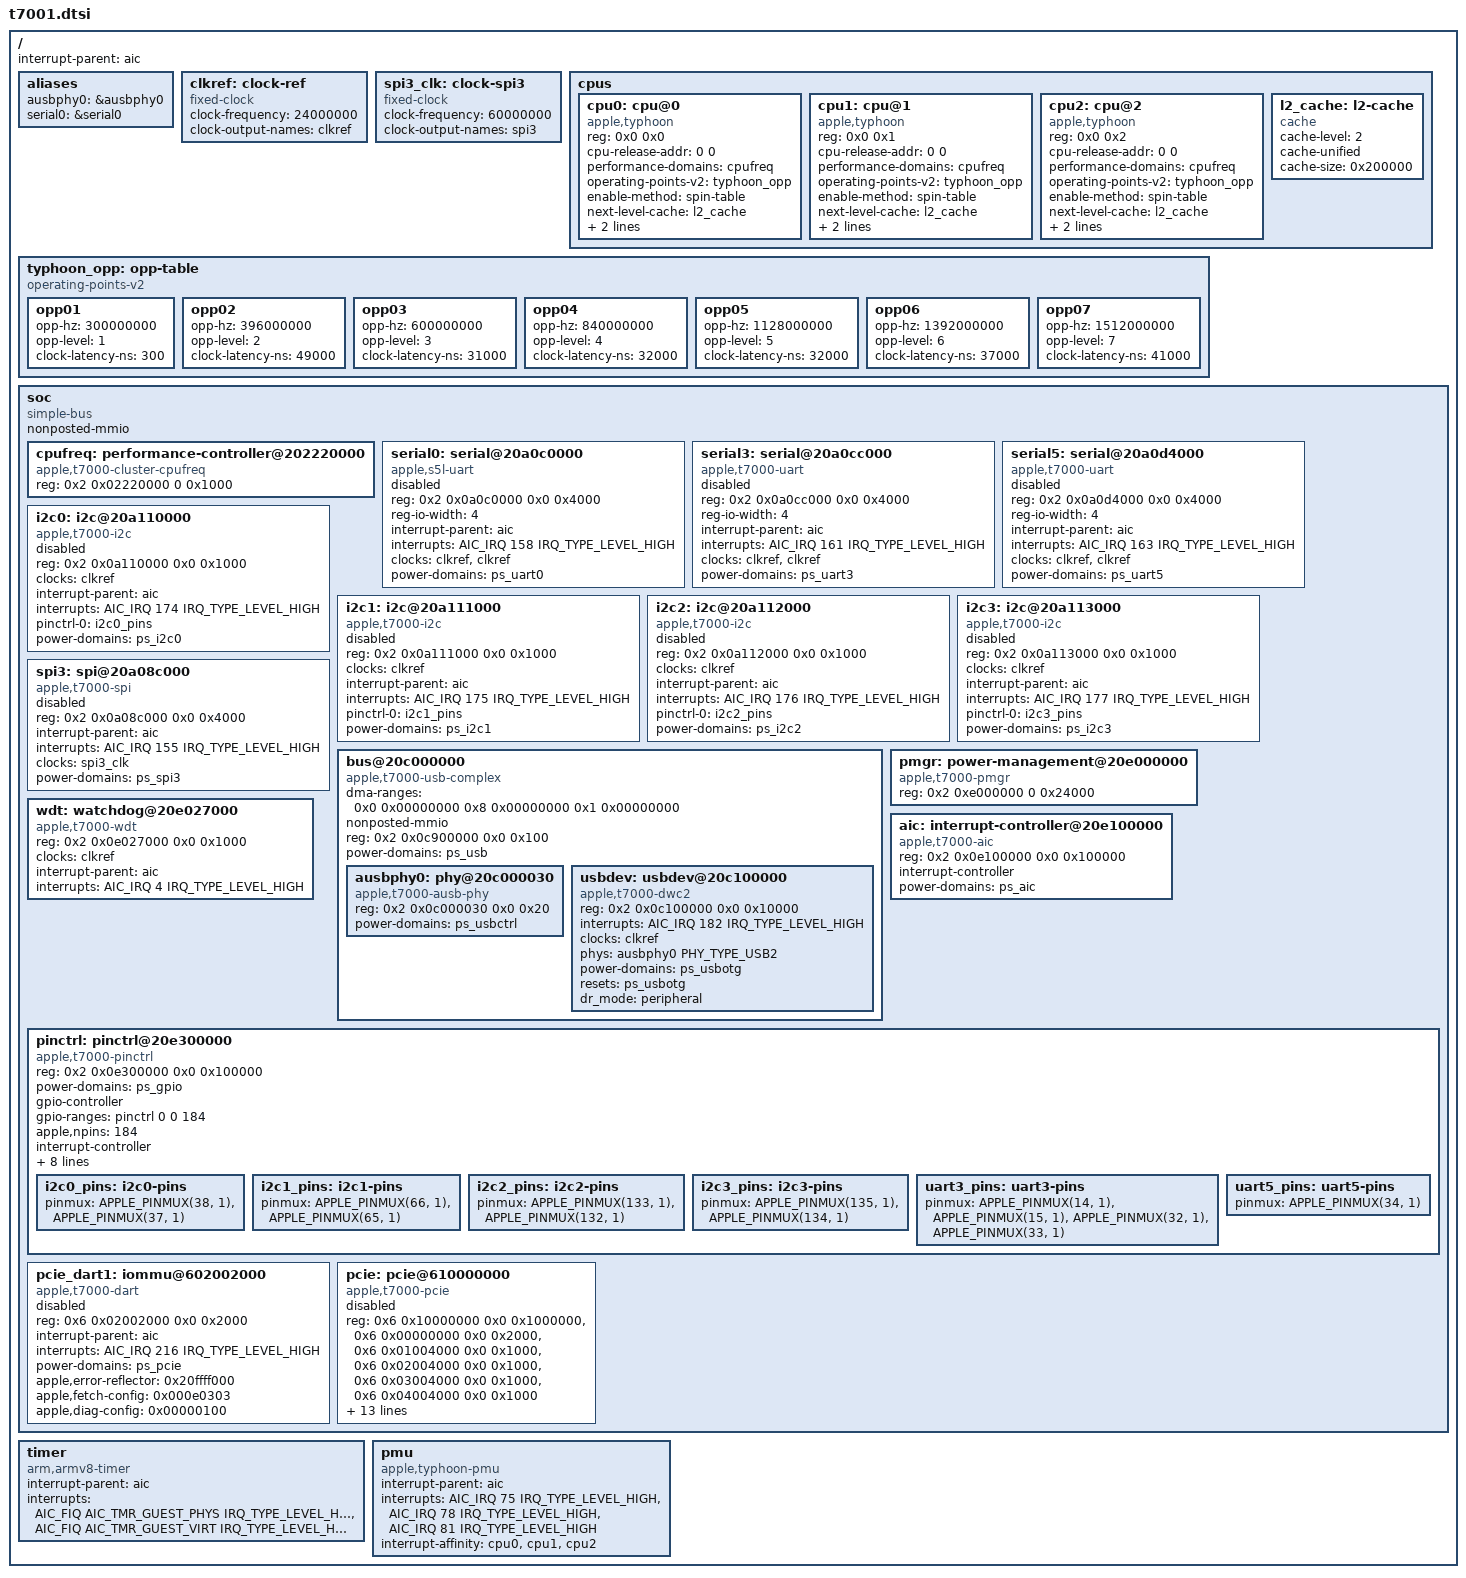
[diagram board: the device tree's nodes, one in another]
// SPDX-License-Identifier: GPL-2.0+ OR MIT
/*
 * Apple T7001 "A8X" SoC
 *
 * Copyright (c) 2022, Konrad Dybcio <konradybcio@kernel.org>
 * Based on Asahi Linux's M1 (t8103.dtsi) and Corellium's A10 efforts.
 */

#include <dt-bindings/gpio/gpio.h>
#include <dt-bindings/interrupt-controller/apple-aic.h>
#include <dt-bindings/interrupt-controller/irq.h>
#include <dt-bindings/phy/phy.h>
#include <dt-bindings/pinctrl/apple.h>

/ {
	interrupt-parent = <&aic>;
	#address-cells = <2>;
	#size-cells = <2>;

	aliases {
		ausbphy0 = &ausbphy0; /* Used by loader */
		serial0 = &serial0;
	};

	clkref: clock-ref {
		compatible = "fixed-clock";
		#clock-cells = <0>;
		clock-frequency = <24000000>;
		clock-output-names = "clkref";
	};

	spi3_clk: clock-spi3 {
		compatible = "fixed-clock";
		#clock-cells = <0>;
		/* ADT clock ID 0x12e: clock-frequencies[46]. */
		clock-frequency = <60000000>;
		clock-output-names = "spi3";
	};

	cpus {
		#address-cells = <2>;
		#size-cells = <0>;

		cpu0: cpu@0 {
			compatible = "apple,typhoon";
			reg = <0x0 0x0>;
			cpu-release-addr = <0 0>; /* To be filled in by loader */
			performance-domains = <&cpufreq>;
			operating-points-v2 = <&typhoon_opp>;
			enable-method = "spin-table";
			device_type = "cpu";
			next-level-cache = <&l2_cache>;
			i-cache-size = <0x10000>;
			d-cache-size = <0x10000>;
		};

		cpu1: cpu@1 {
			compatible = "apple,typhoon";
			reg = <0x0 0x1>;
			cpu-release-addr = <0 0>; /* To be filled in by loader */
			performance-domains = <&cpufreq>;
			operating-points-v2 = <&typhoon_opp>;
			enable-method = "spin-table";
			device_type = "cpu";
			next-level-cache = <&l2_cache>;
			i-cache-size = <0x10000>;
			d-cache-size = <0x10000>;
		};

		cpu2: cpu@2 {
			compatible = "apple,typhoon";
			reg = <0x0 0x2>;
			cpu-release-addr = <0 0>; /* To be filled by loader */
			performance-domains = <&cpufreq>;
			operating-points-v2 = <&typhoon_opp>;
			enable-method = "spin-table";
			device_type = "cpu";
			next-level-cache = <&l2_cache>;
			i-cache-size = <0x10000>;
			d-cache-size = <0x10000>;
		};

		l2_cache: l2-cache {
			compatible = "cache";
			cache-level = <2>;
			cache-unified;
			cache-size = <0x200000>;
		};
	};

	typhoon_opp: opp-table {
		compatible = "operating-points-v2";

		opp01 {
			opp-hz = /bits/ 64 <300000000>;
			opp-level = <1>;
			clock-latency-ns = <300>;
		};
		opp02 {
			opp-hz = /bits/ 64 <396000000>;
			opp-level = <2>;
			clock-latency-ns = <49000>;
		};
		opp03 {
			opp-hz = /bits/ 64 <600000000>;
			opp-level = <3>;
			clock-latency-ns = <31000>;
		};
		opp04 {
			opp-hz = /bits/ 64 <840000000>;
			opp-level = <4>;
			clock-latency-ns = <32000>;
		};
		opp05 {
			opp-hz = /bits/ 64 <1128000000>;
			opp-level = <5>;
			clock-latency-ns = <32000>;
		};
		opp06 {
			opp-hz = /bits/ 64 <1392000000>;
			opp-level = <6>;
			clock-latency-ns = <37000>;
		};
		opp07 {
			opp-hz = /bits/ 64 <1512000000>;
			opp-level = <7>;
			clock-latency-ns = <41000>;
		};
	};

	soc {
		compatible = "simple-bus";
		#address-cells = <2>;
		#size-cells = <2>;
		nonposted-mmio;
		ranges;

		cpufreq: performance-controller@202220000 {
			compatible = "apple,t7000-cluster-cpufreq", "apple,s5l8960x-cluster-cpufreq";
			reg = <0x2 0x02220000 0 0x1000>;
			#performance-domain-cells = <0>;
		};

		serial0: serial@20a0c0000 {
			compatible = "apple,s5l-uart";
			reg = <0x2 0x0a0c0000 0x0 0x4000>;
			reg-io-width = <4>;
			interrupt-parent = <&aic>;
			interrupts = <AIC_IRQ 158 IRQ_TYPE_LEVEL_HIGH>;
			/* Use the bootloader-enabled clocks for now. */
			clocks = <&clkref>, <&clkref>;
			clock-names = "uart", "clk_uart_baud0";
			power-domains = <&ps_uart0>;
			status = "disabled";
		};

		serial3: serial@20a0cc000 {
			compatible = "apple,t7000-uart", "apple,t8010-uart", "apple,s5l-uart";
			reg = <0x2 0x0a0cc000 0x0 0x4000>;
			reg-io-width = <4>;
			interrupt-parent = <&aic>;
			interrupts = <AIC_IRQ 161 IRQ_TYPE_LEVEL_HIGH>;
			clocks = <&clkref>, <&clkref>;
			clock-names = "uart", "clk_uart_baud0";
			power-domains = <&ps_uart3>;
			status = "disabled";
		};

		serial5: serial@20a0d4000 {
			compatible = "apple,t7000-uart", "apple,t8010-uart", "apple,s5l-uart";
			reg = <0x2 0x0a0d4000 0x0 0x4000>;
			reg-io-width = <4>;
			interrupt-parent = <&aic>;
			interrupts = <AIC_IRQ 163 IRQ_TYPE_LEVEL_HIGH>;
			clocks = <&clkref>, <&clkref>;
			clock-names = "uart", "clk_uart_baud0";
			power-domains = <&ps_uart5>;
			status = "disabled";
		};

		i2c0: i2c@20a110000 {
			compatible = "apple,t7000-i2c", "apple,i2c";
			reg = <0x2 0x0a110000 0x0 0x1000>;
			clocks = <&clkref>;
			interrupt-parent = <&aic>;
			interrupts = <AIC_IRQ 174 IRQ_TYPE_LEVEL_HIGH>;
			pinctrl-0 = <&i2c0_pins>;
			pinctrl-names = "default";
			power-domains = <&ps_i2c0>;
			#address-cells = <1>;
			#size-cells = <0>;
			status = "disabled";
		};

		i2c1: i2c@20a111000 {
			compatible = "apple,t7000-i2c", "apple,i2c";
			reg = <0x2 0x0a111000 0x0 0x1000>;
			clocks = <&clkref>;
			interrupt-parent = <&aic>;
			interrupts = <AIC_IRQ 175 IRQ_TYPE_LEVEL_HIGH>;
			pinctrl-0 = <&i2c1_pins>;
			pinctrl-names = "default";
			power-domains = <&ps_i2c1>;
			#address-cells = <1>;
			#size-cells = <0>;
			status = "disabled";
		};

		i2c2: i2c@20a112000 {
			compatible = "apple,t7000-i2c", "apple,i2c";
			reg = <0x2 0x0a112000 0x0 0x1000>;
			clocks = <&clkref>;
			interrupt-parent = <&aic>;
			interrupts = <AIC_IRQ 176 IRQ_TYPE_LEVEL_HIGH>;
			pinctrl-0 = <&i2c2_pins>;
			pinctrl-names = "default";
			power-domains = <&ps_i2c2>;
			#address-cells = <1>;
			#size-cells = <0>;
			status = "disabled";
		};

		i2c3: i2c@20a113000 {
			compatible = "apple,t7000-i2c", "apple,i2c";
			reg = <0x2 0x0a113000 0x0 0x1000>;
			clocks = <&clkref>;
			interrupt-parent = <&aic>;
			interrupts = <AIC_IRQ 177 IRQ_TYPE_LEVEL_HIGH>;
			pinctrl-0 = <&i2c3_pins>;
			pinctrl-names = "default";
			power-domains = <&ps_i2c3>;
			#address-cells = <1>;
			#size-cells = <0>;
			status = "disabled";
		};

		spi3: spi@20a08c000 {
			compatible = "apple,t7000-spi", "apple,spi";
			reg = <0x2 0x0a08c000 0x0 0x4000>;
			interrupt-parent = <&aic>;
			interrupts = <AIC_IRQ 155 IRQ_TYPE_LEVEL_HIGH>;
			clocks = <&spi3_clk>;
			power-domains = <&ps_spi3>;
			#address-cells = <1>;
			#size-cells = <0>;
			status = "disabled";
		};

		bus@20c000000 {
			compatible = "apple,t7000-usb-complex", "apple,s5l8960x-usb-complex", "simple-pm-bus";
			#address-cells = <2>;
			#size-cells = <2>;
			dma-ranges = <0x0 0x00000000 0x8 0x00000000 0x1 0x00000000>;
			nonposted-mmio;
			ranges;

			reg = <0x2 0x0c900000 0x0 0x100>;
			power-domains = <&ps_usb>;

			ausbphy0: phy@20c000030 {
				compatible = "apple,t7000-ausb-phy", "apple,ausb-phy";
				reg = <0x2 0x0c000030 0x0 0x20>;
				power-domains = <&ps_usbctrl>;
				#phy-cells = <1>;
				/* Tunables to be filled by loader */
			};

			usbdev: usbdev@20c100000 {
				compatible = "apple,t7000-dwc2", "apple,dwc2";
				reg = <0x2 0x0c100000 0x0 0x10000>;
				interrupts = <AIC_IRQ 182 IRQ_TYPE_LEVEL_HIGH>;
				clocks = <&clkref>;
				clock-names = "otg";
				phys = <&ausbphy0 PHY_TYPE_USB2>;
				phy-names = "usb2-phy";
				power-domains = <&ps_usbotg>;
				resets = <&ps_usbotg>;
				dr_mode = "peripheral";
			};
#if 0
			ehci0: usb-ehci@20c200000 {
				compatible = "apple,t7000-ehci", "generic-ehci";
				reg = <0x2 0x0c200000 0x0 0x10000>;
				interrupts = <AIC_IRQ 183 IRQ_TYPE_LEVEL_HIGH>;
				power-domains = <&ps_usb2host0>;
			};

			ohci0: usb-ohci@20c300000 {
				compatible = "apple,t7000-ohci", "generic-ohci";
				reg = <0x2 0x0c300000 0x0 0x10000>;
				interrupts = <AIC_IRQ 184 IRQ_TYPE_LEVEL_HIGH>;
				power-domains = <&ps_usb2host0_ohci>;
			};

			ehci1: usb-ehci@20c400000 {
				compatible = "apple,t7000-ehci", "generic-ehci";
				reg = <0x2 0x0c400000 0x0 0x10000>;
				interrupts = <AIC_IRQ 185 IRQ_TYPE_LEVEL_HIGH>;
				power-domains = <&ps_usb2host1>;
			};

			ehci2: usb-ehci@20c500000 {
				compatible = "apple,t7000-ehci", "generic-ehci";
				reg = <0x2 0x0c500000 0x0 0x10000>;
				interrupts = <AIC_IRQ 186 IRQ_TYPE_LEVEL_HIGH>;
				power-domains = <&ps_usb2host2>;
			};
#endif
		};


		pmgr: power-management@20e000000 {
			compatible = "apple,t7000-pmgr", "apple,pmgr", "syscon", "simple-mfd";
			#address-cells = <1>;
			#size-cells = <1>;

			reg = <0x2 0xe000000 0 0x24000>;
		};

		wdt: watchdog@20e027000 {
			compatible = "apple,t7000-wdt", "apple,wdt";
			reg = <0x2 0x0e027000 0x0 0x1000>;
			clocks = <&clkref>;
			interrupt-parent = <&aic>;
			interrupts = <AIC_IRQ 4 IRQ_TYPE_LEVEL_HIGH>;
		};

		aic: interrupt-controller@20e100000 {
			compatible = "apple,t7000-aic", "apple,aic";
			reg = <0x2 0x0e100000 0x0 0x100000>;
			#interrupt-cells = <3>;
			interrupt-controller;
			power-domains = <&ps_aic>;
		};

		pinctrl: pinctrl@20e300000 {
			compatible = "apple,t7000-pinctrl", "apple,pinctrl";
			reg = <0x2 0x0e300000 0x0 0x100000>;
			power-domains = <&ps_gpio>;

			gpio-controller;
			#gpio-cells = <2>;
			gpio-ranges = <&pinctrl 0 0 184>;
			apple,npins = <184>;

			interrupt-controller;
			#interrupt-cells = <2>;
			interrupt-parent = <&aic>;
			interrupts = <AIC_IRQ 62 IRQ_TYPE_LEVEL_HIGH>,
				     <AIC_IRQ 63 IRQ_TYPE_LEVEL_HIGH>,
				     <AIC_IRQ 64 IRQ_TYPE_LEVEL_HIGH>,
				     <AIC_IRQ 65 IRQ_TYPE_LEVEL_HIGH>,
				     <AIC_IRQ 66 IRQ_TYPE_LEVEL_HIGH>,
				     <AIC_IRQ 67 IRQ_TYPE_LEVEL_HIGH>,
				     <AIC_IRQ 68 IRQ_TYPE_LEVEL_HIGH>;

			i2c0_pins: i2c0-pins {
				pinmux = <APPLE_PINMUX(38, 1)>,
					 <APPLE_PINMUX(37, 1)>;
			};

			i2c1_pins: i2c1-pins {
				pinmux = <APPLE_PINMUX(66, 1)>,
					 <APPLE_PINMUX(65, 1)>;
			};

			i2c2_pins: i2c2-pins {
				pinmux = <APPLE_PINMUX(133, 1)>,
					 <APPLE_PINMUX(132, 1)>;
			};

			i2c3_pins: i2c3-pins {
				pinmux = <APPLE_PINMUX(135, 1)>,
					 <APPLE_PINMUX(134, 1)>;
			};

			uart3_pins: uart3-pins {
				pinmux = <APPLE_PINMUX(14, 1)>,
					 <APPLE_PINMUX(15, 1)>,
					 <APPLE_PINMUX(32, 1)>,
					 <APPLE_PINMUX(33, 1)>;
			};

			uart5_pins: uart5-pins {
				pinmux = <APPLE_PINMUX(34, 1)>;
			};
		};

		/*
		 * The ADT gives this DART 2 MiB, which covers the PCIe port 1
		 * window at 0x602004000; its registers end below 0x100.
		 */
		pcie_dart1: iommu@602002000 {
			compatible = "apple,t7000-dart", "apple,s5l8960x-dart";
			reg = <0x6 0x02002000 0x0 0x2000>;
			#iommu-cells = <5>;
			interrupt-parent = <&aic>;
			interrupts = <AIC_IRQ 216 IRQ_TYPE_LEVEL_HIGH>;
			power-domains = <&ps_pcie>;
			/* ADT dart-apcie1: error-reflector, fetch-config, diag-config */
			apple,error-reflector = /bits/ 64 <0x20ffff000>;
			apple,fetch-config = <0x000e0303>;
			apple,diag-config = <0x00000100>;
			status = "disabled";
		};

		pcie: pcie@610000000 {
			compatible = "apple,t7000-pcie";
			device_type = "pci";
			reg = <0x6 0x10000000 0x0 0x1000000>,
			      <0x6 0x00000000 0x0 0x2000>,
			      <0x6 0x01004000 0x0 0x1000>,
			      <0x6 0x02004000 0x0 0x1000>,
			      <0x6 0x03004000 0x0 0x1000>,
			      <0x6 0x04004000 0x0 0x1000>;
			reg-names = "config", "rc", "port0", "port1", "port2", "port3";
			interrupt-parent = <&aic>;
			interrupts = <AIC_IRQ 212 IRQ_TYPE_LEVEL_HIGH>,
				     <AIC_IRQ 215 IRQ_TYPE_LEVEL_HIGH>,
				     <AIC_IRQ 218 IRQ_TYPE_LEVEL_HIGH>,
				     <AIC_IRQ 221 IRQ_TYPE_LEVEL_HIGH>;
			interrupt-names = "port0", "port1", "port2", "port3";
			msi-controller;
			msi-parent = <&pcie>;
			msi-ranges = <&aic AIC_IRQ 224 IRQ_TYPE_EDGE_RISING 32>;
			apple,msi-doorbell = <0xbffff000>;
			bus-range = <0 4>;
			#address-cells = <3>;
			#size-cells = <2>;
			ranges = <0x43000000 0x6 0x20000000 0x6 0x20000000 0x1 0xa0000000>,
				 <0x02000000 0x0 0xc0000000 0x7 0xc0000000 0x0 0x40000000>;
			power-domains = <&ps_pcie>, <&ps_pcie_ref>, <&ps_pcie_aux>;
			status = "disabled";
		};
	};

	timer {
		compatible = "arm,armv8-timer";
		interrupt-parent = <&aic>;
		interrupt-names = "phys", "virt";
		/* Note that A8X doesn't actually have a hypervisor (EL2 is not implemented). */
		interrupts = <AIC_FIQ AIC_TMR_GUEST_PHYS IRQ_TYPE_LEVEL_HIGH>,
			     <AIC_FIQ AIC_TMR_GUEST_VIRT IRQ_TYPE_LEVEL_HIGH>;
	};

	pmu {
		compatible = "apple,typhoon-pmu";
		interrupt-parent = <&aic>;
		interrupts = <AIC_IRQ 75 IRQ_TYPE_LEVEL_HIGH>,
			     <AIC_IRQ 78 IRQ_TYPE_LEVEL_HIGH>,
			     <AIC_IRQ 81 IRQ_TYPE_LEVEL_HIGH>;
		interrupt-affinity = <&cpu0 &cpu1 &cpu2>;
	};
};

#include "t7001-pmgr.dtsi"
